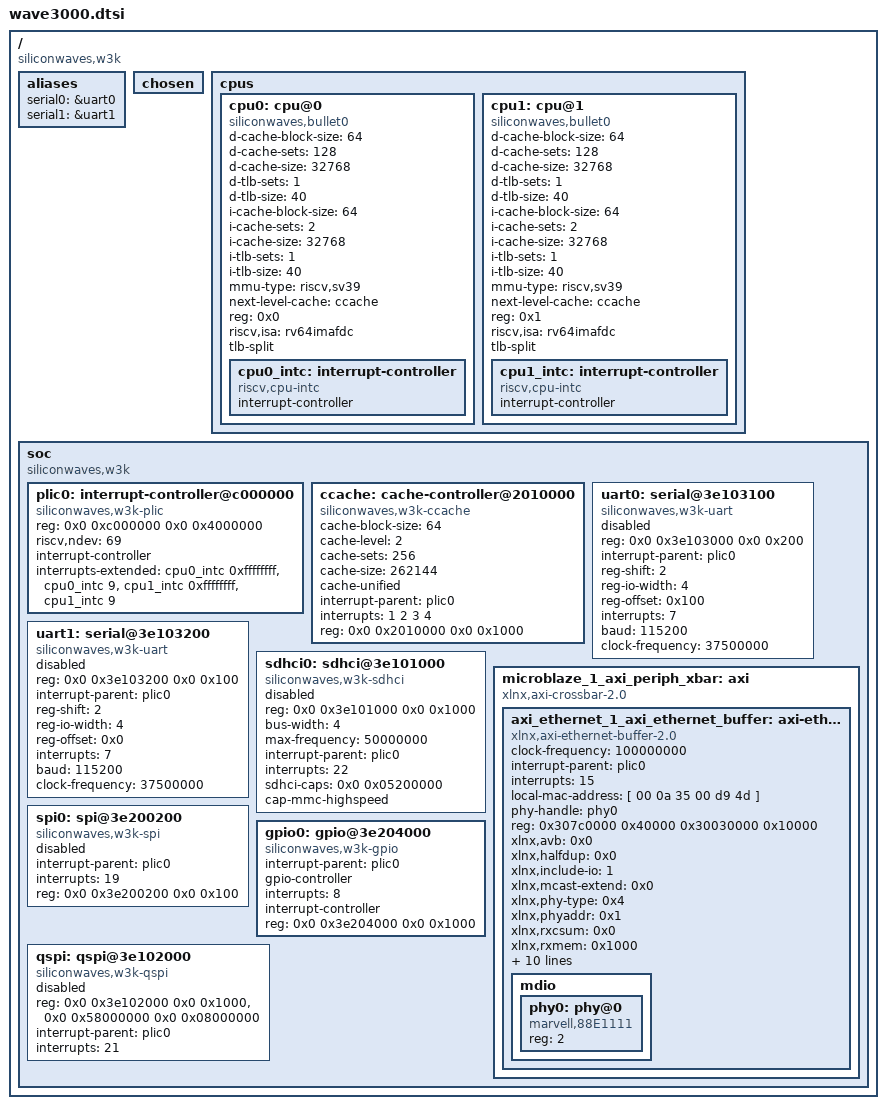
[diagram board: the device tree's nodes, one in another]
// SPDX-License-Identifier: (GPL-2.0 OR MIT)
/* Copyright (c) 2023-2024 Siliconwaves, Inc */

/dts-v1/;
/ {
	#address-cells = <2>;
	#size-cells = <2>;
	compatible = "siliconwaves,w3k";

	aliases {
		serial0 = &uart0;
		serial1 = &uart1;
	};

	chosen {
	};

	cpus {
		#address-cells = <1>;
		#size-cells = <0>;
		cpu0: cpu@0 {
			compatible = "siliconwaves,bullet0", "riscv";
			d-cache-block-size = <64>;
			d-cache-sets = <128>;
			d-cache-size = <32768>;
			d-tlb-sets = <1>;
			d-tlb-size = <40>;
			device_type = "cpu";
			i-cache-block-size = <64>;
			i-cache-sets = <2>;
			i-cache-size = <32768>;
			i-tlb-sets = <1>;
			i-tlb-size = <40>;
			mmu-type = "riscv,sv39";
			next-level-cache = <&ccache>;
			reg = <0x0>;
			riscv,isa = "rv64imafdc";
			tlb-split;
			cpu0_intc: interrupt-controller {
				#interrupt-cells = <1>;
				compatible = "riscv,cpu-intc";
				interrupt-controller;
			};
		};
		cpu1: cpu@1 {
			compatible = "siliconwaves,bullet0", "riscv";
			d-cache-block-size = <64>;
			d-cache-sets = <128>;
			d-cache-size = <32768>;
			d-tlb-sets = <1>;
			d-tlb-size = <40>;
			device_type = "cpu";
			i-cache-block-size = <64>;
			i-cache-sets = <2>;
			i-cache-size = <32768>;
			i-tlb-sets = <1>;
			i-tlb-size = <40>;
			mmu-type = "riscv,sv39";
			next-level-cache = <&ccache>;
			reg = <0x1>;
			riscv,isa = "rv64imafdc";
			tlb-split;
			cpu1_intc: interrupt-controller {
				#interrupt-cells = <1>;
				compatible = "riscv,cpu-intc";
				interrupt-controller;
			};
		};
	};
	soc {
		#address-cells = <2>;
		#size-cells = <2>;
		compatible = "siliconwaves,w3k", "simple-bus";
		ranges;
		plic0: interrupt-controller@c000000 {
			#interrupt-cells = <1>;
			compatible = "siliconwaves,w3k-plic";
			reg = <0x0 0xc000000 0x0 0x4000000>;
			riscv,ndev = <69>;
			interrupt-controller;
			interrupts-extended = <
				&cpu0_intc 0xffffffff &cpu0_intc 9
				&cpu1_intc 0xffffffff &cpu1_intc 9>;
		};
		ccache: cache-controller@2010000 {
			compatible = "siliconwaves,w3k-ccache", "cache";
			cache-block-size = <64>;
			cache-level = <2>;
			cache-sets = <256>;
			cache-size = <262144>;
			cache-unified;
			interrupt-parent = <&plic0>;
			interrupts = <1 2 3 4>;
			reg = <0x0 0x2010000 0x0 0x1000>;
		};
		uart0: serial@3e103100 {
			compatible = "siliconwaves,w3k-uart";
			reg = <0x0 0x3e103000 0x0 0x200>;
			interrupt-parent = <&plic0>;
			reg-shift = <2>;
			reg-io-width = <4>;
			reg-offset = <0x100>;
			interrupts = <7>;
			baud = <115200>;
			clock-frequency = <37500000>;
			status = "disabled";
		};
		uart1: serial@3e103200 {
			compatible = "siliconwaves,w3k-uart";
			reg = <0x0 0x3e103200 0x0 0x100>;
			interrupt-parent = <&plic0>;
			reg-shift = <2>;
			reg-io-width = <4>;
			reg-offset = <0x0>;
			interrupts = <7>;
			baud = <115200>;
			clock-frequency = <37500000>;
			status = "disabled";
		};
		sdhci0: sdhci@3e101000 {
			compatible = "siliconwaves,w3k-sdhci";
			reg = <0x0 0x3e101000 0x0 0x1000>;
			bus-width = <4>;
			max-frequency = <50000000>;
			interrupt-parent = <&plic0>;
			interrupts = <22>;
			sdhci-caps = <0x0 0x05200000>;
			cap-mmc-highspeed;
			status = "disabled";
		};

		microblaze_1_axi_periph_xbar: axi {
			#address-cells = <1>;
			#size-cells = <1>;
			#interrupt-cells = <1>;
			compatible = "xlnx,axi-crossbar-2.0", "simple-bus";
			ranges;
			axi_ethernet_1_axi_ethernet_buffer: axi-ethernet@307c0000 {
				clock-frequency = <100000000>;
				compatible = "xlnx,axi-ethernet-buffer-2.0", "xlnx,axi-ethernet-3.01.a", "xlnx,axi-ethernet-1.00.a";
				device_type = "network";
				interrupt-parent = <&plic0>;
				interrupts = <15>;
				local-mac-address = [ 00 0a 35 00 d9 4d ];
				phy-handle = <&phy0>;
				reg = < 0x307c0000 0x40000 0x30030000 0x10000 >;
				xlnx,avb = <0x0>;
				xlnx,halfdup = <0x0>;
				xlnx,include-io = "1";
				xlnx,mcast-extend = <0x0>;
				xlnx,phy-type = <0x4>;
				xlnx,phyaddr = <0x1>;
				xlnx,rxcsum = <0x0>;
				xlnx,rxmem = <0x1000>;
				xlnx,rxvlan-strp = <0x0>;
				xlnx,rxvlan-tag = <0x0>;
				xlnx,rxvlan-tran = <0x0>;
				xlnx,stats = <0x0>;
				xlnx,txcsum = <0x0>;
				xlnx,txmem = <0x1000>;
				xlnx,txvlan-strp = <0x0>;
				xlnx,txvlan-tag = <0x0>;
				xlnx,txvlan-tran = <0x0>;
				xlnx,type = <0x1>;
				mdio {
					#address-cells = <1>;
					#size-cells = <0>;
					phy0: phy@0 {
						compatible = "marvell,88E1111", "ethernet-phy-ieee802.3-c45";
						device_type = "ethernet-phy";
						reg = <2>;
					};
				};
			};
		};
		spi0: spi@3e200200 {
			compatible = "siliconwaves,w3k-spi";
			interrupt-parent = <&plic0>;
			interrupts = <19>;
			reg = <0x0 0x3e200200 0x0 0x100>;
			status = "disabled";
		};
		gpio0: gpio@3e204000 {
			compatible = "siliconwaves,w3k-gpio";
			interrupt-parent = <&plic0>;
			#interrupt-cells = <1>;
			gpio-controller;
			#gpio-cells = <2>;
			interrupts = <8>;
			interrupt-controller;
			reg = <0x0 0x3e204000 0x0 0x1000>;
		};
		qspi: qspi@3e102000 {
			compatible = "siliconwaves,w3k-qspi";
			reg = <0x0 0x3e102000 0x0 0x1000>,
					<0x0 0x58000000 0x0 0x08000000>;
			interrupt-parent = <&plic0>;
			interrupts = <21>;
			status = "disabled";
		};
	};
};
